# STM32WB35CCU6A register map
File version: 1.0
Registers are 32-bit, access not given, reset 0x0 unless marked. A register's access mark holds for its fields unless they carry their own. Offsets are from the block's base; [hi:lo] are bit positions; {n}, {i} and the like mark numbered series; 'fields as' and 'values as' point back to an identical list.

## TSC
Base 0x40024000
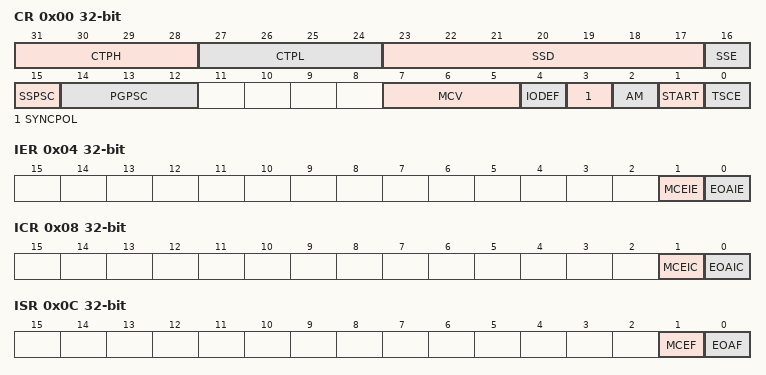
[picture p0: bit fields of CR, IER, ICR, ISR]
0x00 CR
  [31:28] CTPH, [27:24] CTPL, [23:17] SSD, [16] SSE, [15] SSPSC, [14:12] PGPSC, [7:5] MCV, [4] IODEF, [3] SYNCPOL, [2] AM, [1] START, [0] TSCE
0x04 IER
  [1] MCEIE, [0] EOAIE
0x08 ICR
  [1] MCEIC, [0] EOAIC
0x0C ISR
  [1] MCEF, [0] EOAF
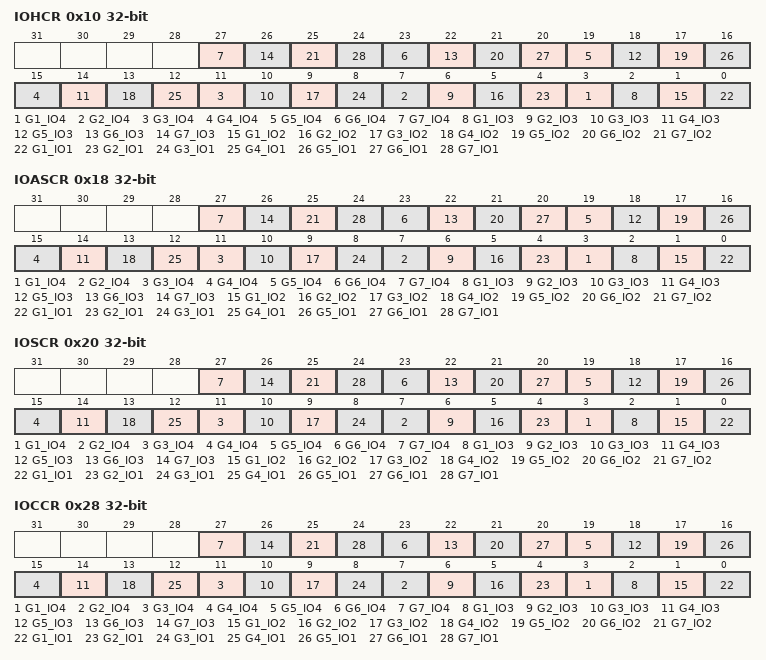
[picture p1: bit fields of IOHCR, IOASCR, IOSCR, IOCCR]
0x10 IOHCR
  [4n-1] G{n}_IO4 (n=1..7), [4n-2] G{n}_IO3 (n=1..7), [4n-3] G{n}_IO2 (n=1..7), [4n-4] G{n}_IO1 (n=1..7)
0x18 IOASCR
  fields as IOHCR
0x20 IOSCR
  fields as IOHCR
0x28 IOCCR
  fields as IOHCR
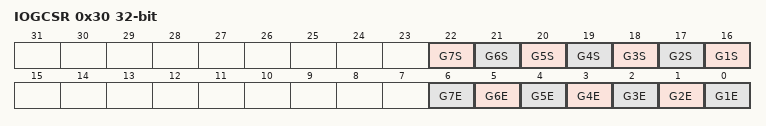
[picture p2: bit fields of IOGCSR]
0x30 IOGCSR
  [n+15] G{n}S (n=1..7), [n-1] G{n}E (n=1..7)
{0x30+4i} IOG{i}CR (i=1..7)
  [13:0] CNT

## GPIOA
Base 0x48000000
Same registers: GPIOB 0x48000400, GPIOC 0x48000800, GPIOD 0x48000C00
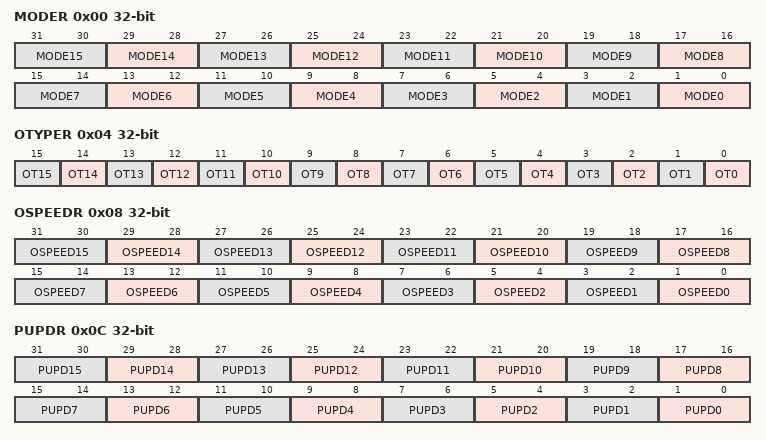
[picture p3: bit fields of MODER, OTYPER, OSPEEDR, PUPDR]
0x00 MODER
  [2n+1:2n] MODE{n} (n=0..15)
0x04 OTYPER
  [n] OT{n} (n=0..15)
0x08 OSPEEDR
  [2n+1:2n] OSPEED{n} (n=0..15)
0x0C PUPDR
  [2n+1:2n] PUPD{n} (n=0..15)
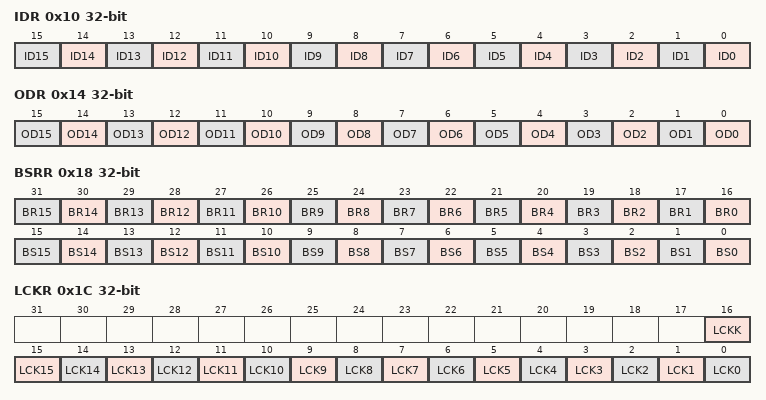
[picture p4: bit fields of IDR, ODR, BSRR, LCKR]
0x10 IDR
  [n] ID{n} (n=0..15)
0x14 ODR
  [n] OD{n} (n=0..15)
0x18 BSRR
  [n+16] BR{n} (n=0..15), [n] BS{n} (n=0..15)
0x1C LCKR
  [16] LCKK, [n] LCK{n} (n=0..15)
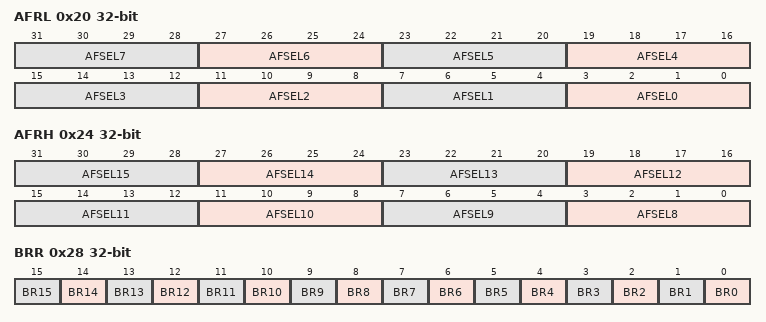
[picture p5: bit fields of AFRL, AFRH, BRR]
0x20 AFRL
  [4n+3:4n] AFSEL{n} (n=0..7)
0x24 AFRH
  [4n-29:4n-32] AFSEL{n} (n=8..15)
0x28 BRR
  [n] BR{n} (n=0..15)

## GPIOE
Base 0x48001000
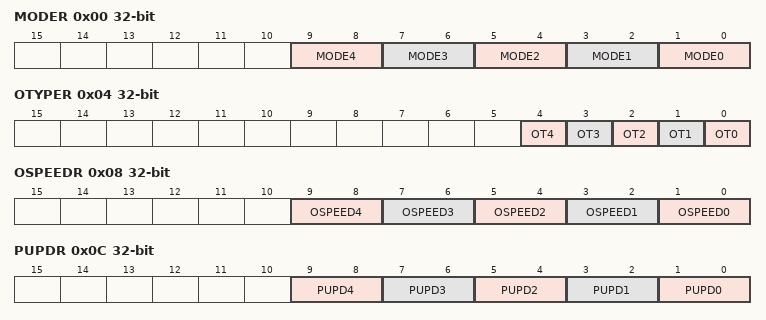
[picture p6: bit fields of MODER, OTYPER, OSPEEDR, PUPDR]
0x00 MODER
  [2n+1:2n] MODE{n} (n=0..4)
0x04 OTYPER
  [n] OT{n} (n=0..4)
0x08 OSPEEDR
  [2n+1:2n] OSPEED{n} (n=0..4)
0x0C PUPDR
  [2n+1:2n] PUPD{n} (n=0..4)
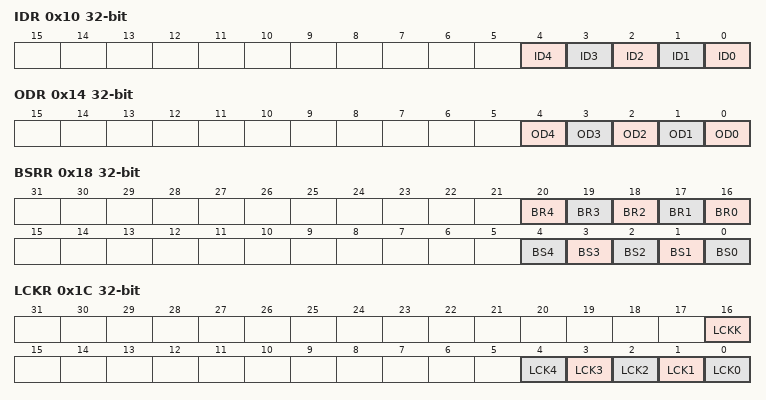
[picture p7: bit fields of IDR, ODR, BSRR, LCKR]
0x10 IDR
  [n] ID{n} (n=0..4)
0x14 ODR
  [n] OD{n} (n=0..4)
0x18 BSRR
  [n+16] BR{n} (n=0..4), [n] BS{n} (n=0..4)
0x1C LCKR
  [16] LCKK, [n] LCK{n} (n=0..4)
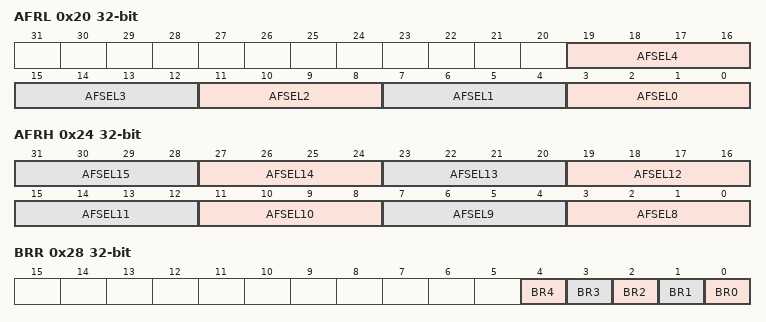
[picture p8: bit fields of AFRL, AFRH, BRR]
0x20 AFRL
  [4n+3:4n] AFSEL{n} (n=0..4)
0x24 AFRH
  [4n-29:4n-32] AFSEL{n} (n=8..15)
0x28 BRR
  [n] BR{n} (n=0..4)

## GPIOH
Base 0x48001C00
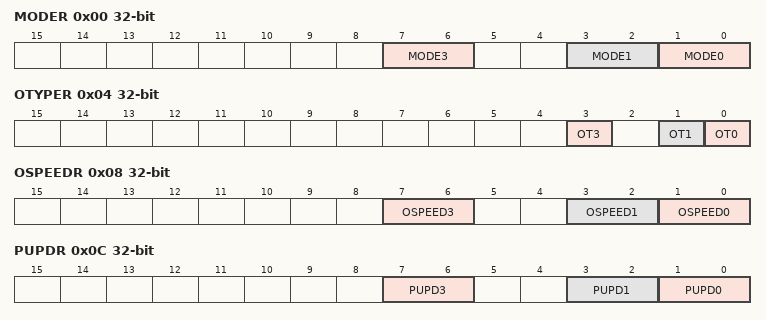
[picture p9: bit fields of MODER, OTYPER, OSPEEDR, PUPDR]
0x00 MODER
  [7:6] MODE3, [3:2] MODE1, [1:0] MODE0
0x04 OTYPER
  [3] OT3, [1] OT1, [0] OT0
0x08 OSPEEDR
  [7:6] OSPEED3, [3:2] OSPEED1, [1:0] OSPEED0
0x0C PUPDR
  [7:6] PUPD3, [3:2] PUPD1, [1:0] PUPD0
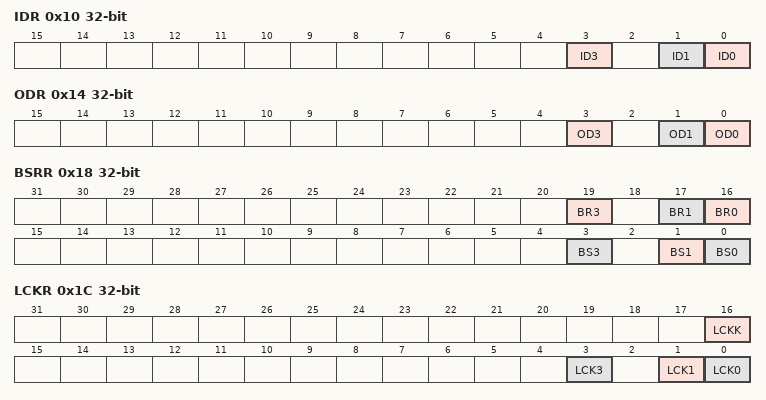
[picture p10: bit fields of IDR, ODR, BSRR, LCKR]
0x10 IDR
  [3] ID3, [1] ID1, [0] ID0
0x14 ODR
  [3] OD3, [1] OD1, [0] OD0
0x18 BSRR
  [19] BR3, [17] BR1, [16] BR0, [3] BS3, [1] BS1, [0] BS0
0x1C LCKR
  [16] LCKK, [3] LCK3, [1] LCK1, [0] LCK0
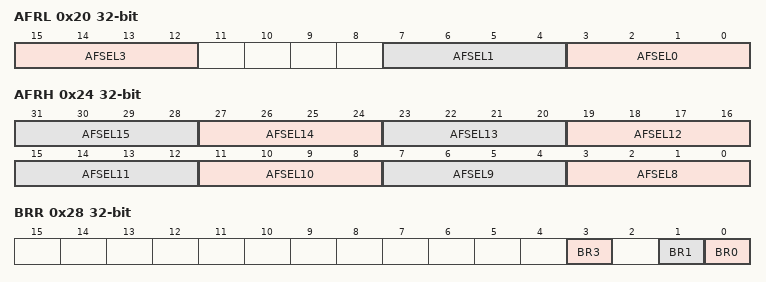
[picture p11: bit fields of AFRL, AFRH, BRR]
0x20 AFRL
  [15:12] AFSEL3, [7:4] AFSEL1, [3:0] AFSEL0
0x24 AFRH
  [4n-29:4n-32] AFSEL{n} (n=8..15)
0x28 BRR
  [3] BR3, [1] BR1, [0] BR0

## ADC
Base 0x50040000
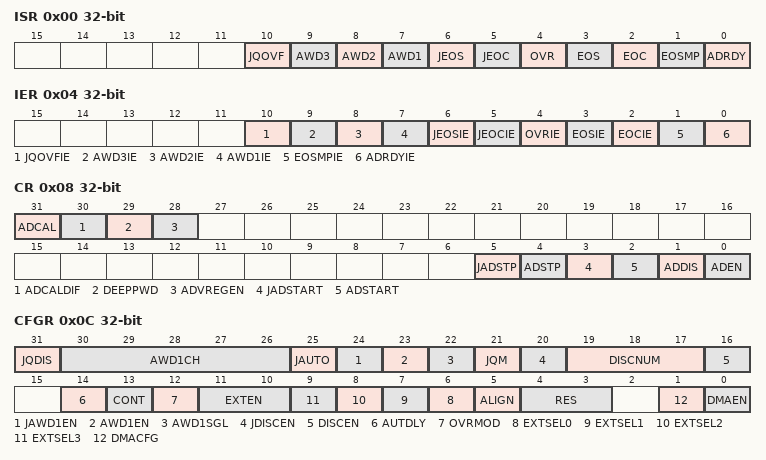
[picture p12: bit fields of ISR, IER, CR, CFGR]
0x00 ISR
  [10] JQOVF, [9] AWD3, [8] AWD2, [7] AWD1, [6] JEOS, [5] JEOC, [4] OVR, [3] EOS, [2] EOC, [1] EOSMP, [0] ADRDY
0x04 IER
  [10] JQOVFIE, [9] AWD3IE, [8] AWD2IE, [7] AWD1IE, [6] JEOSIE, [5] JEOCIE, [4] OVRIE, [3] EOSIE, [2] EOCIE, [1] EOSMPIE, [0] ADRDYIE
0x08 CR
  [31] ADCAL, [30] ADCALDIF, [29] DEEPPWD, [28] ADVREGEN, [5] JADSTP, [4] ADSTP, [3] JADSTART, [2] ADSTART, [1] ADDIS, [0] ADEN
0x0C CFGR
  [31] JQDIS, [30:26] AWD1CH, [25] JAUTO, [24] JAWD1EN, [23] AWD1EN, [22] AWD1SGL, [21] JQM, [20] JDISCEN, [19:17] DISCNUM, [16] DISCEN, [14] AUTDLY, [13] CONT, [12] OVRMOD, [11:10] EXTEN, [n+6] EXTSEL{n} (n=0..3), [5] ALIGN, [4:3] RES, [1] DMACFG, [0] DMAEN
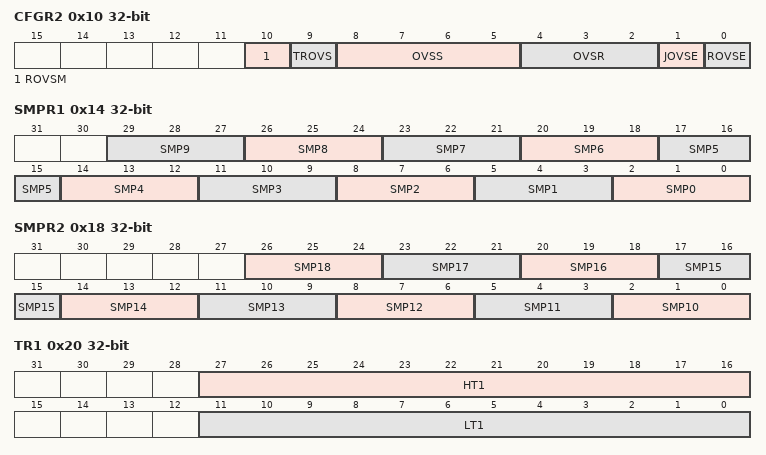
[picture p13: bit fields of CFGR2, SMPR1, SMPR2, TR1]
0x10 CFGR2
  [10] ROVSM, [9] TROVS, [8:5] OVSS, [4:2] OVSR, [1] JOVSE, [0] ROVSE
0x14 SMPR1
  [3n+2:3n] SMP{n} (n=0..9)
0x18 SMPR2
  [3n-28:3n-30] SMP{n} (n=10..18)
0x20 TR1
  [27:16] HT1, [11:0] LT1
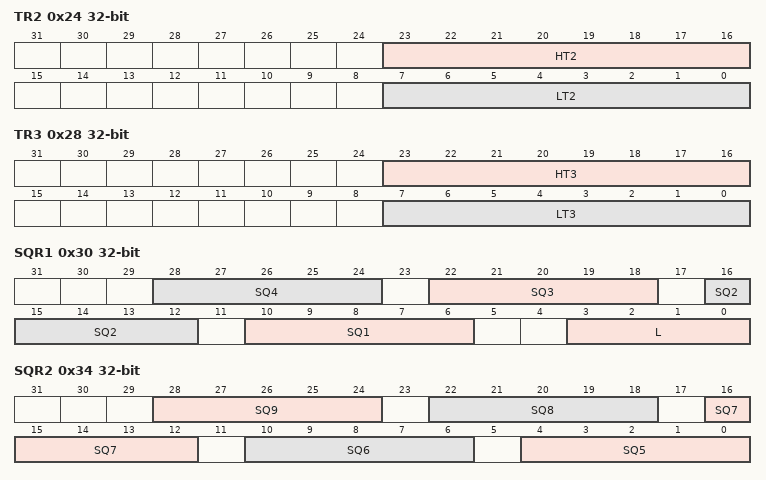
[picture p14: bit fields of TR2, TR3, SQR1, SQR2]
0x24 TR2
  [23:16] HT2, [7:0] LT2
0x28 TR3
  [23:16] HT3, [7:0] LT3
0x30 SQR1
  [6n+4:6n] SQ{n} (n=1..4), [3:0] L
0x34 SQR2
  [6n-26:6n-30] SQ{n} (n=5..9)
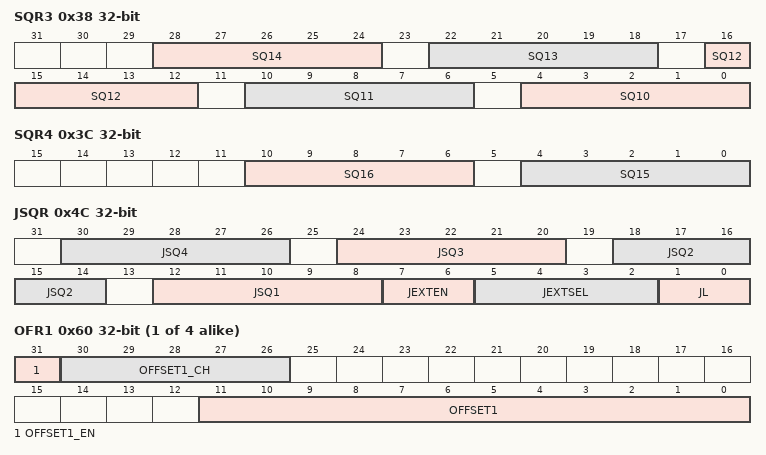
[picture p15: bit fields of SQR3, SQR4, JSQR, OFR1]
0x38 SQR3
  [6n-56:6n-60] SQ{n} (n=10..14)
0x3C SQR4
  [10:6] SQ16, [4:0] SQ15
0x40 DR
  [15:0] RDATA
0x4C JSQR
  [6n+6:6n+2] JSQ{n} (n=1..4), [7:6] JEXTEN, [5:2] JEXTSEL, [1:0] JL
{0x5C+4i} OFR{i} (i=1..4)
  [31] OFFSET{i}_EN, [30:26] OFFSET{i}_CH, [11:0] OFFSET{i}
{0x7C+4i} JDR{i} (i=1..4)
  [15:0] JDATA{i}
0xA0 AWD2CR
  [18:0] AWD2CH
0xA4 AWD3CR
  [18:0] AWD3CH
0xB0 DIFSEL
  [18:0] DIFSEL
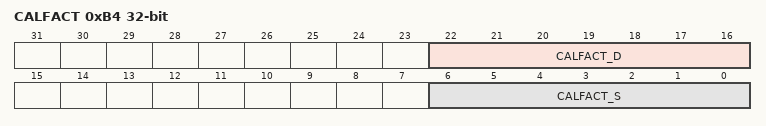
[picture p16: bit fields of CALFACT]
0xB4 CALFACT
  [22:16] CALFACT_D, [6:0] CALFACT_S

## AES1
Base 0x50060000
Same registers: AES2 0x58001800
0x00 CR
  [23:20] NPBLB, [18] KEYSIZE, [14:13] GCMPH, [12] DMAOUTEN, [11] DMAINEN, [10] ERRIE, [9] CCFIE, [8] ERRC, [7] CCFC, [16:5] CHMOD, [4:3] MODE, [2:1] DATATYPE, [0] EN
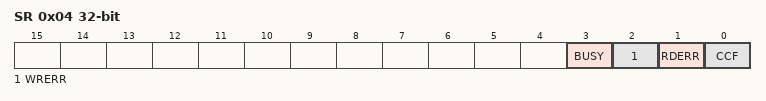
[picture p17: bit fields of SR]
0x04 SR
  [3] BUSY, [2] WRERR, [1] RDERR, [0] CCF
0x08 DINR
  [31:0] DIN
0x0C DOUTR
  [31:0] DOUT
{0x10+4i} KEYR{i} (i=0..3)
  [31:0] KEY
{0x20+4i} IVR{i} (i=0..3)
  [31:0] IVI
{0x20+4i} KEYR{i} (i=4..7)
  [31:0] KEY
{0x40+4i} SUSP{i}R (i=0..7)
  [31:0] SUSP
